VERSION ""

NS_ :

BS_:

BU_: XXX

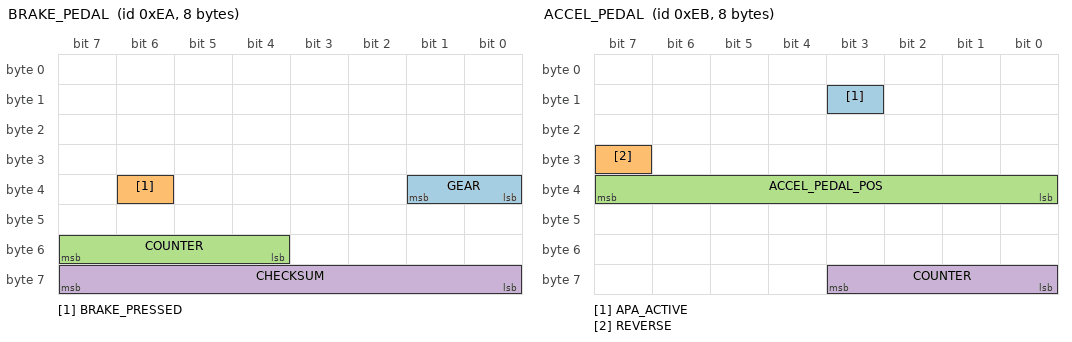
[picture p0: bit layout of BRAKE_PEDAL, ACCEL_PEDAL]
BO_ 234 BRAKE_PEDAL: 8 XXX
 SG_ GEAR : 32|2@1+ (1,0) [0|3] "" XXX
 SG_ BRAKE_PRESSED : 38|1@1+ (1,0) [0|1] "" XXX
 SG_ COUNTER : 52|4@1+ (1,0) [0|15] "" XXX
 SG_ CHECKSUM : 56|8@1+ (1,0) [0|255] "" XXX

BO_ 235 ACCEL_PEDAL: 8 XXX
 SG_ APA_ACTIVE : 11|1@1+ (1,0) [0|1] "" XXX
 SG_ REVERSE : 31|1@1+ (1,0) [0|1] "" XXX
 SG_ ACCEL_PEDAL_POS : 32|8@1+ (0.4,0) [0|102] "%" XXX
 SG_ COUNTER : 56|4@1+ (1,0) [0|15] "" XXX

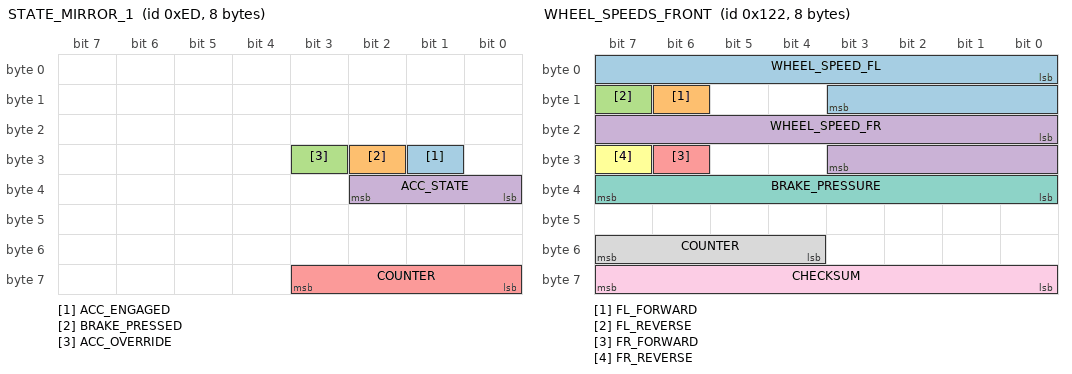
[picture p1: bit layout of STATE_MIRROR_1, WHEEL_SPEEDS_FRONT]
BO_ 237 STATE_MIRROR_1: 8 XXX
 SG_ ACC_ENGAGED : 25|1@1+ (1,0) [0|1] "" XXX
 SG_ BRAKE_PRESSED : 26|1@1+ (1,0) [0|1] "" XXX
 SG_ ACC_OVERRIDE : 27|1@1+ (1,0) [0|1] "" XXX
 SG_ ACC_STATE : 32|3@1+ (1,0) [0|7] "" XXX
 SG_ COUNTER : 56|4@1+ (1,0) [0|15] "" XXX

BO_ 290 WHEEL_SPEEDS_FRONT: 8 XXX
 SG_ WHEEL_SPEED_FL : 0|12@1+ (0.05625,0) [0|230.34] "km/h" XXX
 SG_ FL_FORWARD : 14|1@1+ (1,0) [0|1] "" XXX
 SG_ FL_REVERSE : 15|1@1+ (1,0) [0|1] "" XXX
 SG_ WHEEL_SPEED_FR : 16|12@1+ (0.05625,0) [0|230.34] "km/h" XXX
 SG_ FR_FORWARD : 30|1@1+ (1,0) [0|1] "" XXX
 SG_ FR_REVERSE : 31|1@1+ (1,0) [0|1] "" XXX
 SG_ BRAKE_PRESSURE : 32|8@1+ (1,0) [0|255] "" XXX
 SG_ COUNTER : 52|4@1+ (1,0) [0|15] "" XXX
 SG_ CHECKSUM : 56|8@1+ (1,0) [0|255] "" XXX

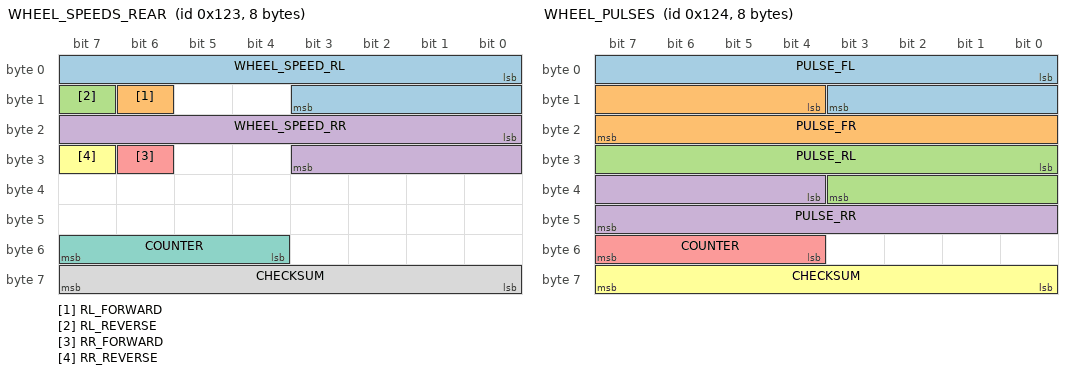
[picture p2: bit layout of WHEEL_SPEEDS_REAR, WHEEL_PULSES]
BO_ 291 WHEEL_SPEEDS_REAR: 8 XXX
 SG_ WHEEL_SPEED_RL : 0|12@1+ (0.05625,0) [0|230.34] "km/h" XXX
 SG_ RL_FORWARD : 14|1@1+ (1,0) [0|1] "" XXX
 SG_ RL_REVERSE : 15|1@1+ (1,0) [0|1] "" XXX
 SG_ WHEEL_SPEED_RR : 16|12@1+ (0.05625,0) [0|230.34] "km/h" XXX
 SG_ RR_FORWARD : 30|1@1+ (1,0) [0|1] "" XXX
 SG_ RR_REVERSE : 31|1@1+ (1,0) [0|1] "" XXX
 SG_ COUNTER : 52|4@1+ (1,0) [0|15] "" XXX
 SG_ CHECKSUM : 56|8@1+ (1,0) [0|255] "" XXX

BO_ 292 WHEEL_PULSES: 8 XXX
 SG_ PULSE_FL : 0|12@1+ (1,0) [0|4095] "" XXX
 SG_ PULSE_FR : 12|12@1+ (1,0) [0|4095] "" XXX
 SG_ PULSE_RL : 24|12@1+ (1,0) [0|4095] "" XXX
 SG_ PULSE_RR : 36|12@1+ (1,0) [0|4095] "" XXX
 SG_ COUNTER : 52|4@1+ (1,0) [0|15] "" XXX
 SG_ CHECKSUM : 56|8@1+ (1,0) [0|255] "" XXX

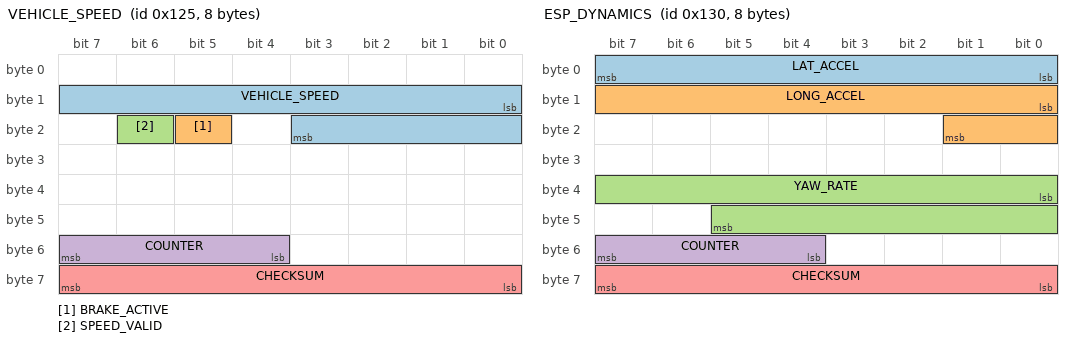
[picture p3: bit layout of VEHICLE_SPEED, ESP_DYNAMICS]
BO_ 293 VEHICLE_SPEED: 8 XXX
 SG_ VEHICLE_SPEED : 8|12@1+ (0.05625,0) [0|230.34] "km/h" XXX
 SG_ BRAKE_ACTIVE : 21|1@1+ (1,0) [0|1] "" XXX
 SG_ SPEED_VALID : 22|1@1+ (1,0) [0|1] "" XXX
 SG_ COUNTER : 52|4@1+ (1,0) [0|15] "" XXX
 SG_ CHECKSUM : 56|8@1+ (1,0) [0|255] "" XXX

BO_ 304 ESP_DYNAMICS: 8 XXX
 SG_ LAT_ACCEL : 0|8@1+ (0.1,-12.8) [-12.8|12.7] "m/s2" XXX
 SG_ LONG_ACCEL : 8|10@1+ (0.03125,-16) [-16|15.97] "m/s2" XXX
 SG_ YAW_RATE : 32|14@1+ (0.01,-81.92) [-81.92|81.91] "deg/s" XXX
 SG_ COUNTER : 52|4@1+ (1,0) [0|15] "" XXX
 SG_ CHECKSUM : 56|8@1+ (1,0) [0|255] "" XXX

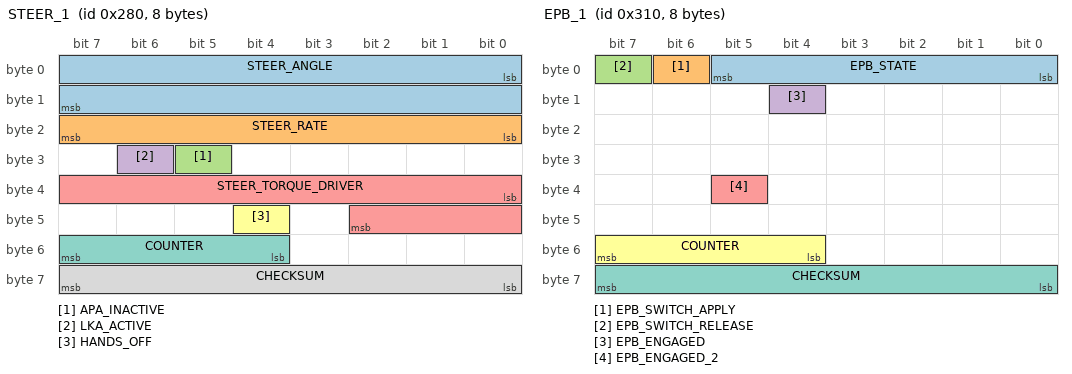
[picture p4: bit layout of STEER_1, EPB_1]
BO_ 640 STEER_1: 8 XXX
 SG_ STEER_ANGLE : 0|16@1+ (-0.1,900) [-900|900] "deg" XXX
 SG_ STEER_RATE : 16|8@1+ (4,0) [0|1020] "deg/s" XXX
 SG_ APA_INACTIVE : 29|1@1+ (1,0) [0|1] "" XXX
 SG_ LKA_ACTIVE : 30|1@1+ (1,0) [0|1] "" XXX
 SG_ STEER_TORQUE_DRIVER : 32|11@1+ (-1,1000) [-1000|1000] "" XXX
 SG_ HANDS_OFF : 44|1@1+ (1,0) [0|1] "" XXX
 SG_ COUNTER : 52|4@1+ (1,0) [0|15] "" XXX
 SG_ CHECKSUM : 56|8@1+ (1,0) [0|255] "" XXX

BO_ 784 EPB_1: 8 XXX
 SG_ EPB_STATE : 0|6@1+ (1,0) [0|63] "" XXX
 SG_ EPB_SWITCH_APPLY : 6|1@1+ (1,0) [0|1] "" XXX
 SG_ EPB_SWITCH_RELEASE : 7|1@1+ (1,0) [0|1] "" XXX
 SG_ EPB_ENGAGED : 12|1@1+ (1,0) [0|1] "" XXX
 SG_ EPB_ENGAGED_2 : 37|1@1+ (1,0) [0|1] "" XXX
 SG_ COUNTER : 52|4@1+ (1,0) [0|15] "" XXX
 SG_ CHECKSUM : 56|8@1+ (1,0) [0|255] "" XXX

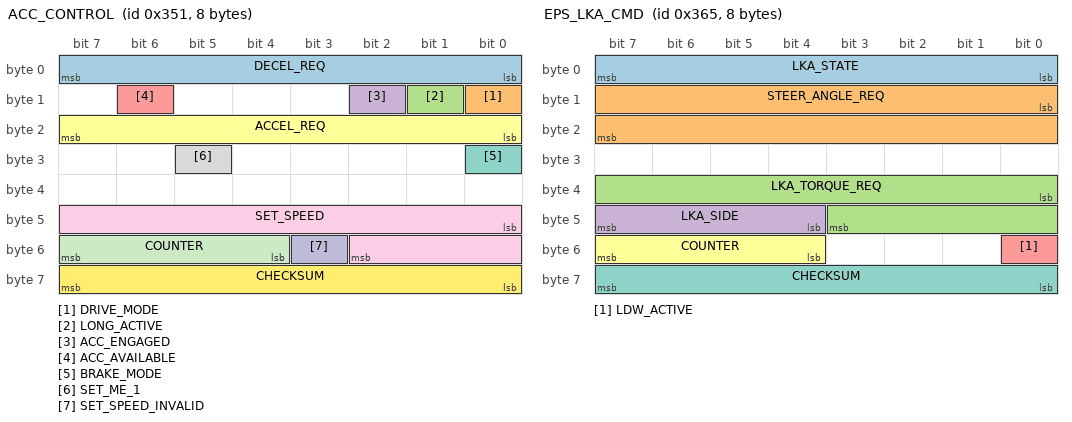
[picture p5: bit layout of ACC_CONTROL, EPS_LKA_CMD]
BO_ 849 ACC_CONTROL: 8 XXX
 SG_ DECEL_REQ : 0|8@1+ (0.05,-5) [-5|7.75] "m/s2" XXX
 SG_ DRIVE_MODE : 8|1@1+ (1,0) [0|1] "" XXX
 SG_ LONG_ACTIVE : 9|1@1+ (1,0) [0|1] "" XXX
 SG_ ACC_ENGAGED : 10|1@1+ (1,0) [0|1] "" XXX
 SG_ ACC_AVAILABLE : 14|1@1+ (1,0) [0|1] "" XXX
 SG_ ACCEL_REQ : 16|8@1+ (0.05,-5) [-5|7.75] "m/s2" XXX
 SG_ BRAKE_MODE : 24|1@1+ (1,0) [0|1] "" XXX
 SG_ SET_ME_1 : 29|1@1+ (1,0) [0|1] "" XXX
 SG_ SET_SPEED : 40|11@1+ (0.1,0) [0|204.7] "km/h" XXX
 SG_ SET_SPEED_INVALID : 51|1@1+ (1,0) [0|1] "" XXX
 SG_ COUNTER : 52|4@1+ (1,0) [0|15] "" XXX
 SG_ CHECKSUM : 56|8@1+ (1,0) [0|255] "" XXX

BO_ 869 EPS_LKA_CMD: 8 XXX
 SG_ LKA_STATE : 0|8@1+ (1,0) [0|255] "" XXX
 SG_ STEER_ANGLE_REQ : 8|16@1+ (-0.1,900) [-900|900] "deg" XXX
 SG_ LKA_TORQUE_REQ : 32|12@1+ (-1,1000) [-3095|1000] "" XXX
 SG_ LKA_SIDE : 44|4@1+ (1,0) [0|15] "" XXX
 SG_ LDW_ACTIVE : 48|1@1+ (1,0) [0|1] "" XXX
 SG_ COUNTER : 52|4@1+ (1,0) [0|15] "" XXX
 SG_ CHECKSUM : 56|8@1+ (1,0) [0|255] "" XXX

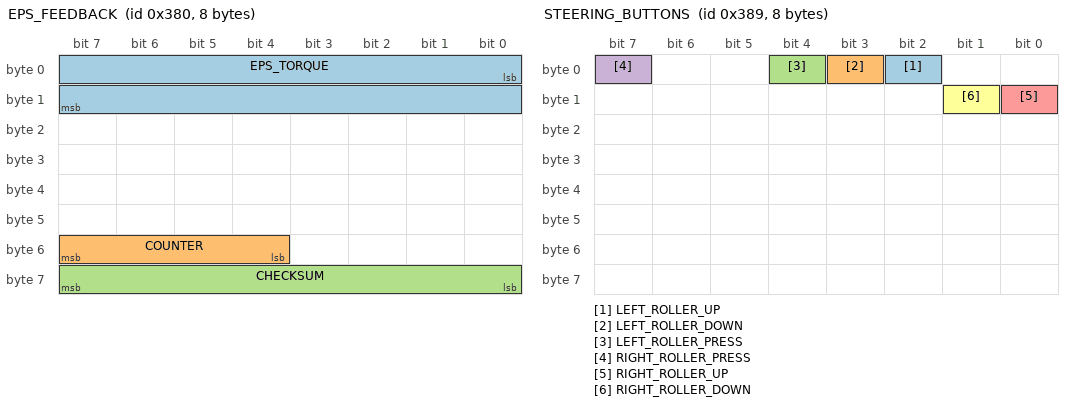
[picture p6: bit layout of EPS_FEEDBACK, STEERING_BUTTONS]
BO_ 896 EPS_FEEDBACK: 8 XXX
 SG_ EPS_TORQUE : 0|16@1+ (-1,20000) [-45535|20000] "" XXX
 SG_ COUNTER : 52|4@1+ (1,0) [0|15] "" XXX
 SG_ CHECKSUM : 56|8@1+ (1,0) [0|255] "" XXX

BO_ 905 STEERING_BUTTONS: 8 XXX
 SG_ LEFT_ROLLER_UP : 2|1@1+ (1,0) [0|1] "" XXX
 SG_ LEFT_ROLLER_DOWN : 3|1@1+ (1,0) [0|1] "" XXX
 SG_ LEFT_ROLLER_PRESS : 4|1@1+ (1,0) [0|1] "" XXX
 SG_ RIGHT_ROLLER_PRESS : 7|1@1+ (1,0) [0|1] "" XXX
 SG_ RIGHT_ROLLER_UP : 8|1@1+ (1,0) [0|1] "" XXX
 SG_ RIGHT_ROLLER_DOWN : 9|1@1+ (1,0) [0|1] "" XXX

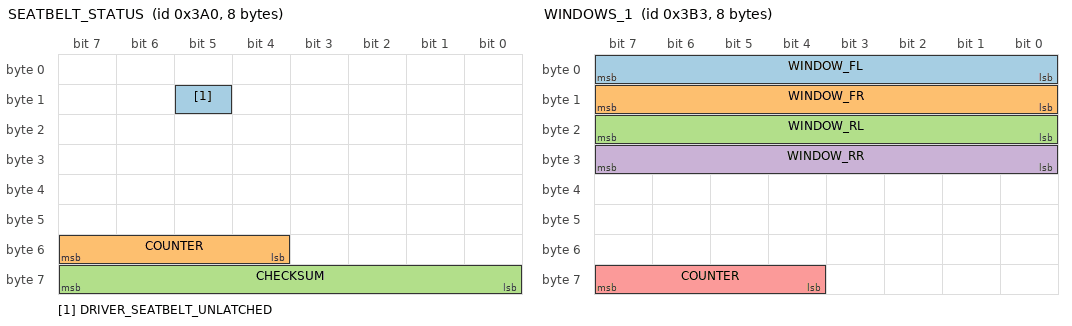
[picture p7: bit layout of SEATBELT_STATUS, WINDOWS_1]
BO_ 928 SEATBELT_STATUS: 8 XXX
 SG_ DRIVER_SEATBELT_UNLATCHED : 13|1@1+ (1,0) [0|1] "" XXX
 SG_ COUNTER : 52|4@1+ (1,0) [0|15] "" XXX
 SG_ CHECKSUM : 56|8@1+ (1,0) [0|255] "" XXX

BO_ 947 WINDOWS_1: 8 XXX
 SG_ WINDOW_FL : 0|8@1+ (1,0) [0|100] "%" XXX
 SG_ WINDOW_FR : 8|8@1+ (1,0) [0|100] "%" XXX
 SG_ WINDOW_RL : 16|8@1+ (1,0) [0|100] "%" XXX
 SG_ WINDOW_RR : 24|8@1+ (1,0) [0|100] "%" XXX
 SG_ COUNTER : 60|4@1+ (1,0) [0|15] "" XXX

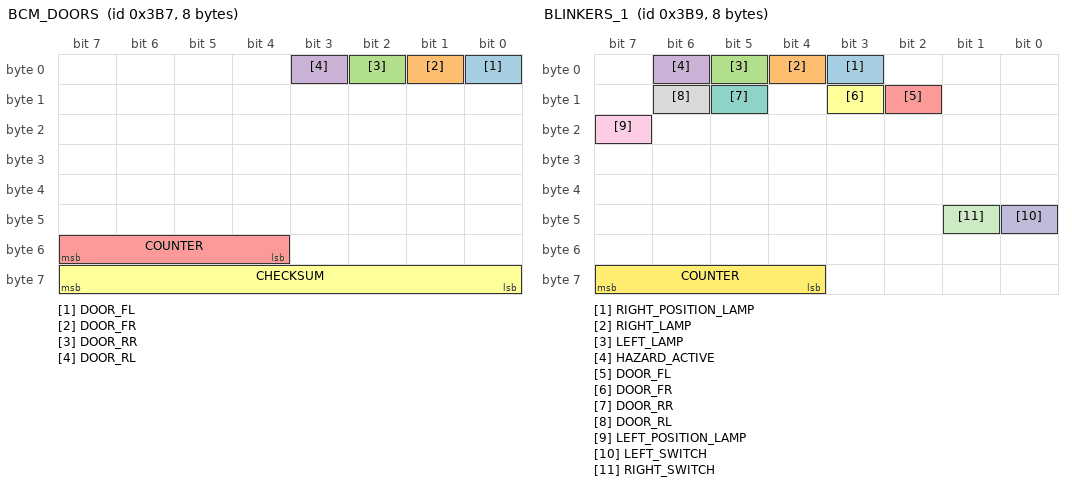
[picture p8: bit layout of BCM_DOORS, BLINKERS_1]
BO_ 951 BCM_DOORS: 8 XXX
 SG_ DOOR_FL : 0|1@1+ (1,0) [0|1] "" XXX
 SG_ DOOR_FR : 1|1@1+ (1,0) [0|1] "" XXX
 SG_ DOOR_RR : 2|1@1+ (1,0) [0|1] "" XXX
 SG_ DOOR_RL : 3|1@1+ (1,0) [0|1] "" XXX
 SG_ COUNTER : 52|4@1+ (1,0) [0|15] "" XXX
 SG_ CHECKSUM : 56|8@1+ (1,0) [0|255] "" XXX

BO_ 953 BLINKERS_1: 8 XXX
 SG_ RIGHT_POSITION_LAMP : 3|1@1+ (1,0) [0|1] "" XXX
 SG_ RIGHT_LAMP : 4|1@1+ (1,0) [0|1] "" XXX
 SG_ LEFT_LAMP : 5|1@1+ (1,0) [0|1] "" XXX
 SG_ HAZARD_ACTIVE : 6|1@1+ (1,0) [0|1] "" XXX
 SG_ DOOR_FL : 10|1@1+ (1,0) [0|1] "" XXX
 SG_ DOOR_FR : 11|1@1+ (1,0) [0|1] "" XXX
 SG_ DOOR_RR : 13|1@1+ (1,0) [0|1] "" XXX
 SG_ DOOR_RL : 14|1@1+ (1,0) [0|1] "" XXX
 SG_ LEFT_POSITION_LAMP : 23|1@1+ (1,0) [0|1] "" XXX
 SG_ LEFT_SWITCH : 40|1@1+ (1,0) [0|1] "" XXX
 SG_ RIGHT_SWITCH : 41|1@1+ (1,0) [0|1] "" XXX
 SG_ COUNTER : 60|4@1+ (1,0) [0|15] "" XXX

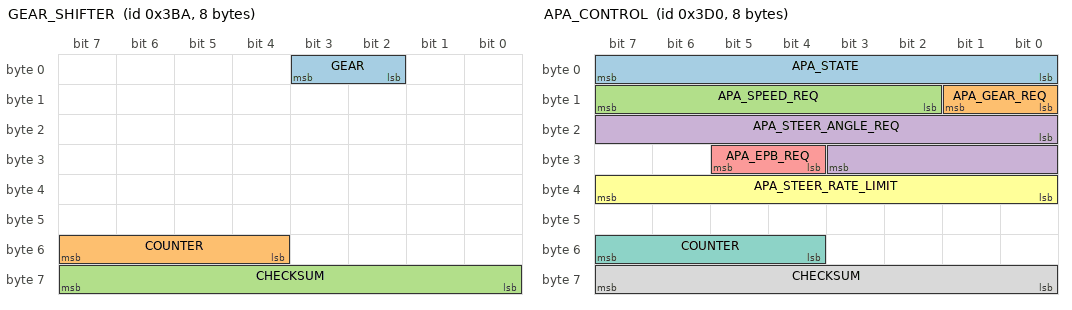
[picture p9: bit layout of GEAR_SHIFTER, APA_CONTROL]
BO_ 954 GEAR_SHIFTER: 8 XXX
 SG_ GEAR : 2|2@1+ (1,0) [0|3] "" XXX
 SG_ COUNTER : 52|4@1+ (1,0) [0|15] "" XXX
 SG_ CHECKSUM : 56|8@1+ (1,0) [0|255] "" XXX

BO_ 976 APA_CONTROL: 8 XXX
 SG_ APA_STATE : 0|8@1+ (1,0) [0|255] "" XXX
 SG_ APA_GEAR_REQ : 8|2@1+ (1,0) [0|3] "" XXX
 SG_ APA_SPEED_REQ : 10|6@1+ (0.125,0) [0|7.875] "km/h" XXX
 SG_ APA_STEER_ANGLE_REQ : 16|12@1+ (-1,900) [-900|900] "deg" XXX
 SG_ APA_EPB_REQ : 28|2@1+ (1,0) [0|3] "" XXX
 SG_ APA_STEER_RATE_LIMIT : 32|8@1+ (4,0) [0|1020] "deg/s" XXX
 SG_ COUNTER : 52|4@1+ (1,0) [0|15] "" XXX
 SG_ CHECKSUM : 56|8@1+ (1,0) [0|255] "" XXX

BO_ 1774 SPEED_MIRROR: 8 XXX
 SG_ SPEED : 48|16@1+ (0.1,0) [0|6553.5] "km/h" XXX

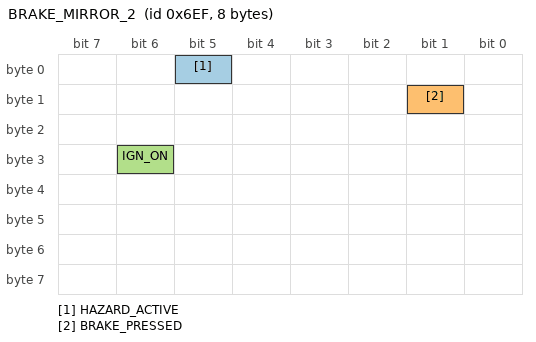
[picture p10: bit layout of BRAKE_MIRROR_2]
BO_ 1775 BRAKE_MIRROR_2: 8 XXX
 SG_ HAZARD_ACTIVE : 5|1@1+ (1,0) [0|1] "" XXX
 SG_ BRAKE_PRESSED : 9|1@1+ (1,0) [0|1] "" XXX
 SG_ IGN_ON : 30|1@1+ (1,0) [0|1] "" XXX

BO_ 1794 ACC_HUD: 8 XXX
 SG_ ACC_STATE : 20|4@1+ (1,0) [0|15] "" XXX

VAL_ 237 ACC_STATE 5 "ACTIVE" 6 "APA" ;
VAL_ 1794 ACC_STATE 5 "ACTIVE" 6 "APA" ;
VAL_ 234 GEAR 3 "D" 2 "N" 1 "R" ;
VAL_ 869 LKA_STATE 0 "OFF" 1 "STANDBY" 2 "READY" 19 "ACTIVE" ;
VAL_ 869 LKA_SIDE 1 "LEFT_LINE" 2 "RIGHT_LINE" ;
VAL_ 784 EPB_STATE 36 "APPLIED" 40 "RELEASED" 48 "APPLYING" 52 "RELEASING" ;
VAL_ 954 GEAR 3 "D" 2 "N" 1 "R" ;
VAL_ 976 APA_STATE 0 "OFF" 1 "REQUEST" 7 "ACTIVE" 15 "FINISHED" 19 "ABORTED" ;
VAL_ 976 APA_GEAR_REQ 0 "N" 1 "D" 2 "R" ;
VAL_ 976 APA_EPB_REQ 0 "NONE" 1 "RELEASE" 2 "APPLY" ;
